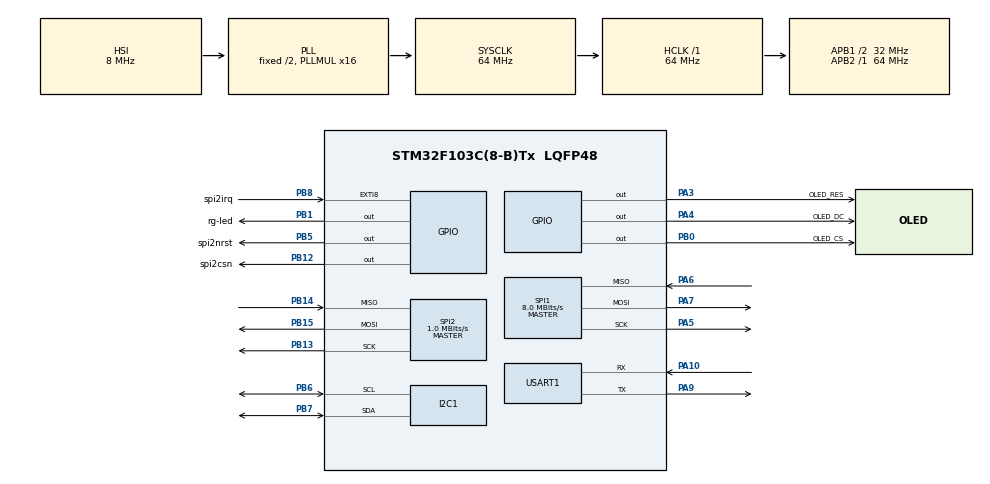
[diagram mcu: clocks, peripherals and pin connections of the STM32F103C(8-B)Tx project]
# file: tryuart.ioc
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Mcu.Family=STM32F1
Mcu.Name=STM32F103C(8-B)Tx
Mcu.Package=LQFP48
NVIC.EXTI9_5_IRQn=true\:1\:0\:false\:false\:true\:true\:true\:true
NVIC.PriorityGroup=NVIC_PRIORITYGROUP_4
NVIC.USART1_IRQn=true\:0\:0\:false\:false\:true\:true\:true\:true
PA10.Mode=Asynchronous
PA10.Signal=USART1_RX
PA13.Mode=Serial_Wire
PA13.Signal=SYS_JTMS-SWDIO
PA14.Mode=Serial_Wire
PA14.Signal=SYS_JTCK-SWCLK
PA3.GPIO_Label=OLED_RES
PA3.Signal=GPIO_Output
PA4.GPIO_Label=OLED_DC
PA4.Signal=GPIO_Output
PA5.Mode=Full_Duplex_Master
PA5.Signal=SPI1_SCK
PA6.Mode=Full_Duplex_Master
PA6.Signal=SPI1_MISO
PA7.Mode=Full_Duplex_Master
PA7.Signal=SPI1_MOSI
PA9.Mode=Asynchronous
PA9.Signal=USART1_TX
PB0.GPIO_Label=OLED_CS
PB0.Signal=GPIO_Output
PB1.GPIO_Label=rg-led
PB1.Signal=GPIO_Output
PB12.GPIO_Label=spi2csn
PB12.PinState=GPIO_PIN_SET
PB12.Signal=GPIO_Output
PB13.Mode=Full_Duplex_Master
PB13.Signal=SPI2_SCK
PB14.Mode=Full_Duplex_Master
PB14.Signal=SPI2_MISO
PB15.Mode=Full_Duplex_Master
PB15.Signal=SPI2_MOSI
PB5.GPIO_Label=spi2nrst
PB5.PinState=GPIO_PIN_SET
PB5.Signal=GPIO_Output
PB6.Mode=I2C
PB6.Signal=I2C1_SCL
PB7.Mode=I2C
PB7.Signal=I2C1_SDA
PB8.GPIO_ModeDefaultEXTI=GPIO_MODE_IT_RISING
PB8.GPIO_Label=spi2irq
PB8.Signal=GPXTI8
PD0-OSC_IN.Mode=HSE-External-Oscillator
PD0-OSC_IN.Signal=RCC_OSC_IN
PD1-OSC_OUT.Mode=HSE-External-Oscillator
PD1-OSC_OUT.Signal=RCC_OSC_OUT
ProjectManager.HeapSize=0x200
ProjectManager.StackSize=0x400
ProjectManager.TargetToolchain=CMake
RCC.AHBFreq_Value=64000000
RCC.APB1CLKDivider=RCC_HCLK_DIV2
RCC.APB1Freq_Value=32000000
RCC.APB1TimFreq_Value=64000000
RCC.APB2Freq_Value=64000000
RCC.APB2TimFreq_Value=64000000
RCC.HCLKFreq_Value=64000000
RCC.PLLMUL=RCC_PLL_MUL16
RCC.SYSCLKFreq_VALUE=64000000
RCC.SYSCLKSource=RCC_SYSCLKSOURCE_PLLCLK
RCC.USBFreq_Value=64000000
SPI1.BaudRatePrescaler=SPI_BAUDRATEPRESCALER_8
SPI1.CalculateBaudRate=8.0 MBits/s
SPI1.Direction=SPI_DIRECTION_2LINES
SPI1.Mode=SPI_MODE_MASTER
SPI1.VirtualType=VM_MASTER
SPI2.BaudRatePrescaler=SPI_BAUDRATEPRESCALER_32
SPI2.CLKPhase=SPI_PHASE_1EDGE
SPI2.CLKPolarity=SPI_POLARITY_LOW
SPI2.CalculateBaudRate=1.0 MBits/s
SPI2.Direction=SPI_DIRECTION_2LINES
SPI2.Mode=SPI_MODE_MASTER
SPI2.VirtualType=VM_MASTER
USART1.VirtualMode=VM_ASYNC
board=custom

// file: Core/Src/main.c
/* USER CODE BEGIN Header */
/**
  ******************************************************************************
  * @file           : main.c
  * @brief          : Main program body
  ******************************************************************************
  * @attention
  *
  * Copyright (c) 2026 STMicroelectronics.
  * All rights reserved.
  *
  * This software is licensed under terms that can be found in the LICENSE file
  * in the root directory of this software component.
  * If no LICENSE file comes with this software, it is provided AS-IS.
  *
  ******************************************************************************
  */
/* USER CODE END Header */
#include "main.h"
#include "i2c.h"
#include "spi.h"
#include "usart.h"
#include "gpio.h"

/* USER CODE BEGIN Includes */
#include <stdio.h>
#include "usart.h"
#include "pan3029.h"
/* USER CODE END Includes */

void SystemClock_Config(void);

int main(void)
{

  /* MCU Configuration--------------------------------------------------------*/

  /* Reset of all peripherals, Initializes the Flash interface and the Systick. */
  HAL_Init();

  /* Configure the system clock */
  SystemClock_Config();

  /* Initialize all configured peripherals */
  MX_GPIO_Init();
  MX_USART1_UART_Init();
  MX_SPI1_Init();
  MX_I2C1_Init();
  MX_SPI2_Init();
  /* USER CODE BEGIN 2 */
  PAN3029_StartContinuousRx();

  /* USER CODE END 2 */

  /* Infinite loop */
  while (1)
  {

    /* USER CODE BEGIN 3 */
    /* --- RG-LED 红绿切换 (PB1) --- */
    HAL_GPIO_TogglePin(rg_led_GPIO_Port, rg_led_Pin);

    /* --- PAN3029 RX node --- */
    PAN3029_RxDebugTask();

    HAL_Delay(10);

  }
  /* USER CODE END 3 */
}

void SystemClock_Config(void)
{
  RCC_OscInitTypeDef RCC_OscInitStruct = {0};
  RCC_ClkInitTypeDef RCC_ClkInitStruct = {0};

  /** Initializes the RCC Oscillators according to the specified parameters
  * in the RCC_OscInitTypeDef structure.
  */
  RCC_OscInitStruct.OscillatorType = RCC_OSCILLATORTYPE_HSI;
  RCC_OscInitStruct.HSIState = RCC_HSI_ON;
  RCC_OscInitStruct.HSICalibrationValue = RCC_HSICALIBRATION_DEFAULT;
  RCC_OscInitStruct.PLL.PLLState = RCC_PLL_ON;
  RCC_OscInitStruct.PLL.PLLSource = RCC_PLLSOURCE_HSI_DIV2;
  RCC_OscInitStruct.PLL.PLLMUL = RCC_PLL_MUL16;
  if (HAL_RCC_OscConfig(&RCC_OscInitStruct) != HAL_OK)
  {
    Error_Handler();
  }

  /** Initializes the CPU, AHB and APB buses clocks
  */
  RCC_ClkInitStruct.ClockType = RCC_CLOCKTYPE_HCLK|RCC_CLOCKTYPE_SYSCLK
                              |RCC_CLOCKTYPE_PCLK1|RCC_CLOCKTYPE_PCLK2;
  RCC_ClkInitStruct.SYSCLKSource = RCC_SYSCLKSOURCE_PLLCLK;
  RCC_ClkInitStruct.AHBCLKDivider = RCC_SYSCLK_DIV1;
  RCC_ClkInitStruct.APB1CLKDivider = RCC_HCLK_DIV2;
  RCC_ClkInitStruct.APB2CLKDivider = RCC_HCLK_DIV1;

  if (HAL_RCC_ClockConfig(&RCC_ClkInitStruct, FLASH_LATENCY_2) != HAL_OK)
  {
    Error_Handler();
  }
}

void Error_Handler(void)
{
  __disable_irq();
  while (1)
  {
  }
}
